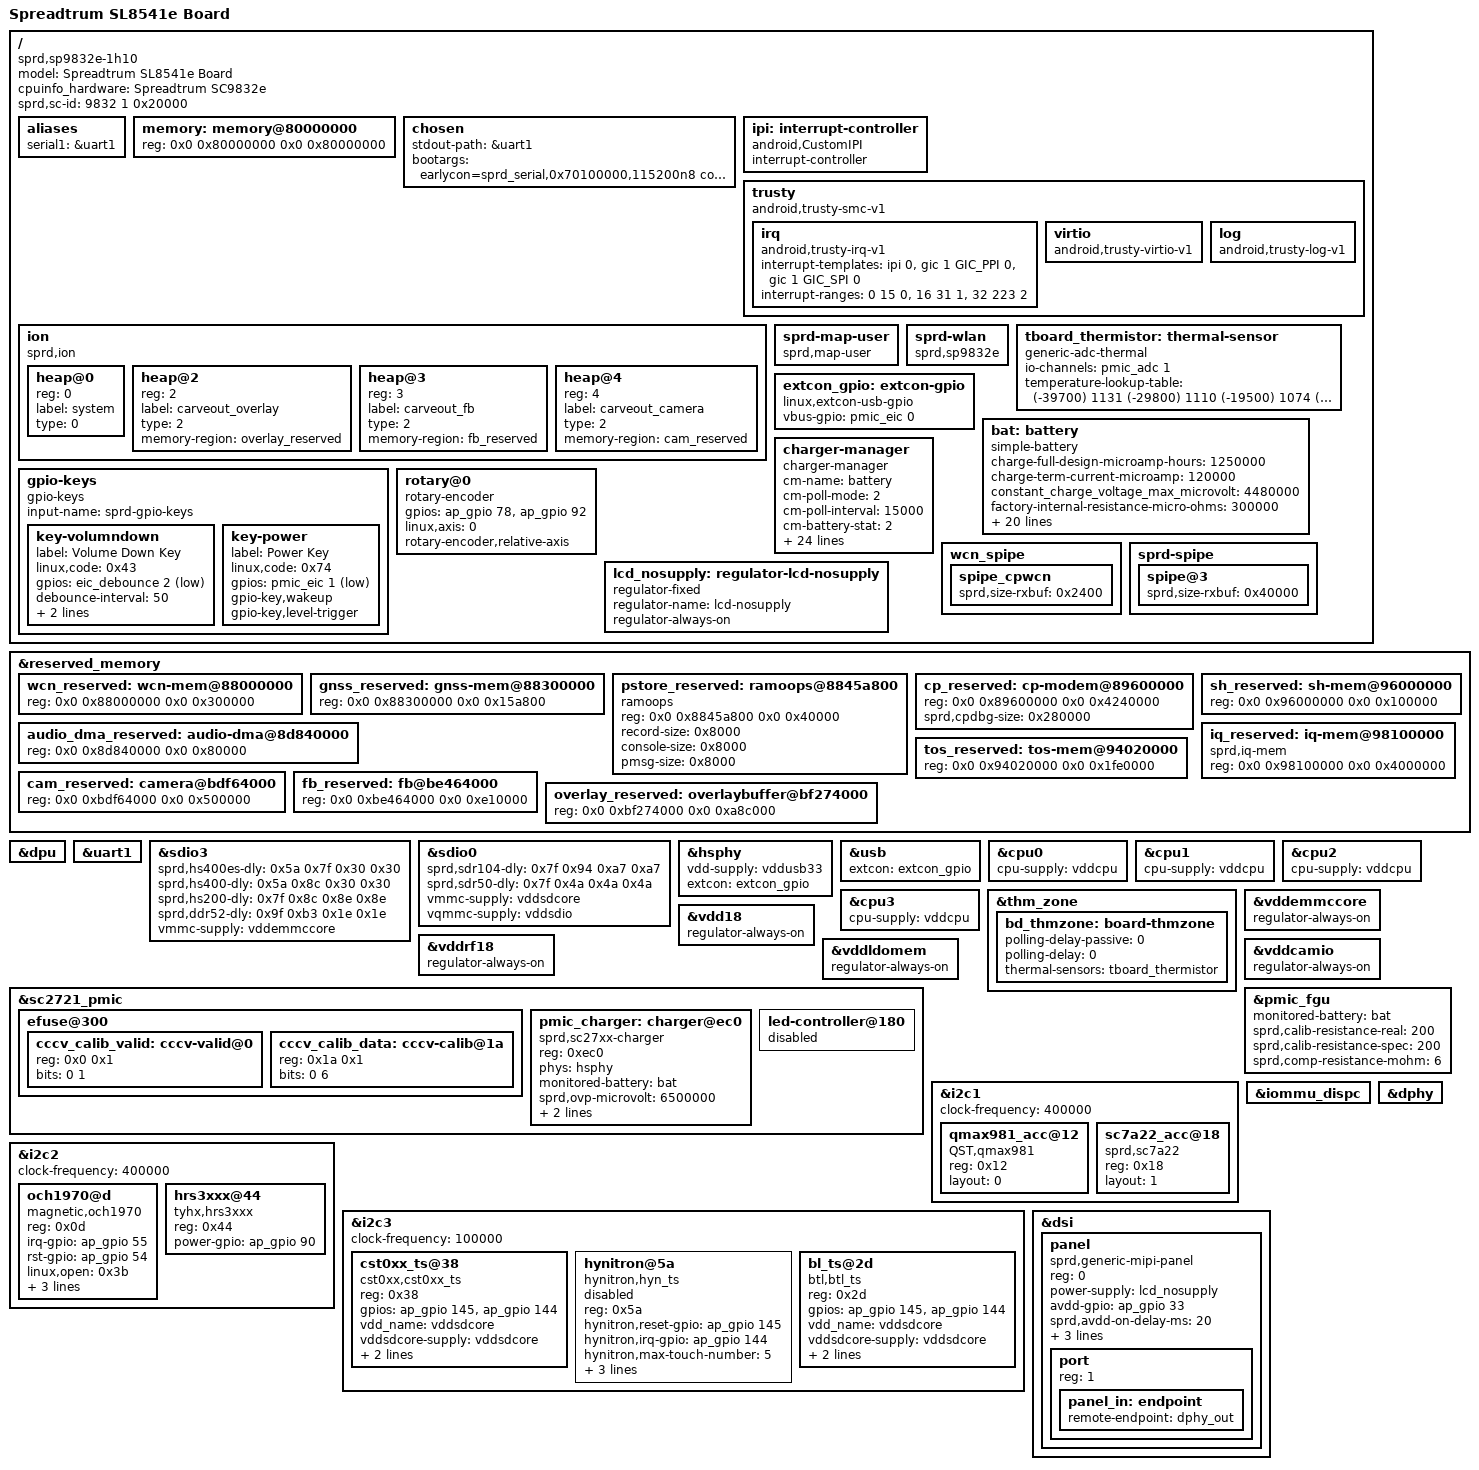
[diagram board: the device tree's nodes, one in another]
/*
 * DM82 watch (SC9832E / SC2721) board DTS for the 4.14 tree
 *
 * Hardware values come from the decompiled stock DT of the watch
 * (devices/dm82/stock.dts and SPEC.md of the 4.4 tree). The binding names are
 * the ones the 4.14 drivers read. devices/dm82/DTS_414.md has the node by node
 * table and the open points; the method is the one of the DM63 and MT108 files
 * (devices/dm63/DTS_414.md, devices/mt108/DTS_414.md).
 *
 * Compile only, nothing here has run on a watch.
 *
 * This file is licensed under a dual GPLv2 or X11 license.
 */
/dts-v1/;

#include <dt-bindings/gpio/gpio.h>
#include "sc9832e.dtsi"
#include "sp9832e-mach.dtsi"
#include "sc9832e-wcn.dtsi"
#include "sc2721.dtsi"
#include "lcd/lcd_co5300_oled175_mipi.dtsi"

/ {
	model = "Spreadtrum SL8541e Board";
	compatible = "sprd,sp9832e-1h10", "sprd,sc9832e";
	cpuinfo_hardware = "Spreadtrum SC9832e";
	sprd,sc-id = <9832 1 0x20000>;

	aliases {
		serial1 = &uart1;
	};

	/* stock: memory@80000000, 2 GiB window (MemTotal is lower, see reserved-memory) */
	memory: memory@80000000 {
		device_type = "memory";
		reg = <0x0 0x80000000 0x0 0x80000000>;
	};

	/* bootargs exactly as stock */
	chosen {
		stdout-path = &uart1;
		bootargs = "earlycon=sprd_serial,0x70100000,115200n8 console=ttyS1,115200n8 loglevel=1 init=/init root=/dev/ram0 rw androidboot.hardware=sl8541e_1h10";
	};

	ipi: interrupt-controller {
		compatible = "android,CustomIPI";
		#interrupt-cells = <1>;
		interrupt-controller;
	};

	trusty {
		compatible = "android,trusty-smc-v1";

		irq {
			compatible = "android,trusty-irq-v1";
			interrupt-templates = <&ipi 0>,
						<&gic 1 GIC_PPI 0>,
						<&gic 1 GIC_SPI 0>;
			interrupt-ranges = < 0  15 0>,
						<16  31 1>,
						<32 223 2>;
		};

		virtio {
			compatible = "android,trusty-virtio-v1";
		};

		log {
			compatible = "android,trusty-log-v1";
		};
	};

	/*
	 * stock ion heaps. The 4.14 sprd_ion driver reads reg, label, type and
	 * memory-region of each child. The stock "phys-offset" property is not
	 * read by 4.14 and is dropped.
	 */
	ion {
		compatible = "sprd,ion";
		#address-cells = <1>;
		#size-cells = <0>;

		heap@0 {
			reg = <0>;
			label = "system";
			type = <0>;
		};

		heap@2 {
			reg = <2>;
			label = "carveout_overlay";
			type = <2>;
			memory-region = <&overlay_reserved>;
		};

		heap@3 {
			reg = <3>;
			label = "carveout_fb";
			type = <2>;
			memory-region = <&fb_reserved>;
		};

		heap@4 {
			reg = <4>;
			label = "carveout_camera";
			type = <2>;
			memory-region = <&cam_reserved>;
		};
	};

	/* 4.14 compatible is "sprd,map-user" (stock: "sprd,sprd_map_user") */
	sprd-map-user {
		compatible = "sprd,map-user";
	};

	sprd-wlan {
		compatible = "sprd,sp9832e";
	};

	/*
	 * Board NTC (stock bd-tsensor@10, io-channel 3). The stock channel
	 * numbers are 4.4 logical channels (even = big scale, odd = small
	 * scale, two per hardware channel): 3 -> ADCI1 = hardware channel 1,
	 * which is the 4.14 channel number. Table: stock temp-tab-val (mV) and
	 * temp-tab-temp ((value - 1000) / 10 degC) converted to the
	 * generic-adc-thermal format (mV, milli degC).
	 */
	tboard_thermistor: thermal-sensor {
		compatible = "generic-adc-thermal";
		#thermal-sensor-cells = <0>;
		io-channels = <&pmic_adc 1>;
		io-channel-names = "sensor-channel";
		temperature-lookup-table = <	(-39700) 1131
						(-29800) 1110
						(-19500) 1074
						(-4800) 983
						10100 838
						24800 654
						44900 413
						54900 316
						64900 238
						74900 178
						84900 133
						94900 100
						104900 75
						114900 57
						124900 43 >;
	};

	/*
	 * USB cable detection. Stock: musb "sprd,cable-detection-method" =
	 * "gpios", "sprd,vbus-gpios" = PMIC EIC 0 (active high), no ID gpio.
	 * 4.14 takes the cable as an extcon device: VBUS from the gpio extcon.
	 */
	extcon_gpio: extcon-gpio {
		compatible = "linux,extcon-usb-gpio";
		vbus-gpio = <&pmic_eic 0 GPIO_ACTIVE_HIGH>;
	};

	/*
	 * Battery (stock "battery" node, sprd,sprd-battery) as a simple-battery
	 * with the property names this tree's power_supply_get_battery_info()
	 * reads (note the underscore name of the two constant_charge_* ones).
	 *
	 *   cnom 0x4e2 = 1250 mAh             charge-full-design-microamp-hours
	 *   rint 0x12c = 300 mOhm             factory-internal-resistance-micro-ohms
	 *   chg-end-cur 0x78 = 120 mA         charge-term-current-microamp
	 *   chg-end-vol 0x1180 = 4480 mV      constant_charge_voltage_max_microvolt
	 *   alm-vol 0xd7a = 3450 mV           voltage-min-design-microvolt
	 *                                     (low voltage alarm, same role, see SC2721_FGU_MAP.md)
	 *   ocv-tab-vol (mV) / ocv-tab-cap    ocv-capacity-table-0 (uV, percent), 20 degC
	 *   temp-tab-val (mV) / temp-tab-temp voltage-temp-table (uV, deci degC + 1000)
	 *                                     (temp-support 1, the table is the DM63 one)
	 *   adp-*-cur / adp-*-cur-limit       charge-*-current-microamp <current limit>
	 *                                     sdp/cdp/dcp 0x28a = 650 mA, unknown 0x276 = 630 mA;
	 *                                     limits 500 / 1500 / 3000 / 500 mA
	 *
	 * 4480 mV is representable by the SC2721 charger model
	 * (sc2721_cv_model()): END_V 1 (4300 mV) plus round(180 / 7.5) = 24 code
	 * steps over the efuse calibration, bit 0 of the code cleared. That holds
	 * for the calibrations 0..39 (code <= 0x3f), the default 0x20 gives code
	 * 56, exactly 4480 mV for even calibrations and 4472.5 mV for odd ones.
	 * For calibrations 40..63 the model cannot represent 4480 mV and
	 * sc2721_set_termination_voltage() returns -EINVAL (nothing written).
	 * The efuse calibration of the unit was not read. The jeita zone CV
	 * below is the stock 4450 mV (representable up to calibration 43).
	 * The stock chg-bat-safety-vol 4500 mV and rechg-vol 4320 mV have no
	 * 4.14 counterpart.
	 *
	 * TODO: stock cnom-temp-tab and rint-temp-tab (capacity and resistance
	 * against temperature) are not mapped: the 4.4 tables are scaled
	 * (cnom 1800/1300/1070/1000 permille, rint 200/450/650/1100 at
	 * 1020/1010/1000/990, same tables as the DM63) and the 4.14
	 * capacity-temp-table and resistance-temp-table use value / 10 degC,
	 * units not proven equal.
	 */
	bat: battery {
		compatible = "simple-battery";
		charge-full-design-microamp-hours = <1250000>;
		charge-term-current-microamp = <120000>;
		constant_charge_voltage_max_microvolt = <4480000>;
		factory-internal-resistance-micro-ohms = <300000>;
		voltage-min-design-microvolt = <3450000>;
		ocv-capacity-celsius = <20>;
		ocv-capacity-table-0 = <4418000 100>, <4350000 95>, <4294000 90>,
				       <4235000 85>, <4175000 80>, <4118000 75>,
				       <4065000 70>, <4016000 65>, <3970000 60>,
				       <3909000 55>, <3873000 50>, <3846000 45>,
				       <3823000 40>, <3805000 35>, <3789000 30>,
				       <3768000 25>, <3749000 20>, <3723000 15>,
				       <3696000 10>, <3681000 5>, <3400000 0>;
		voltage-temp-table = <1052000 750>, <953000 800>, <858000 850>,
				     <762000 900>, <671000 950>, <584000 1000>,
				     <504000 1050>, <434000 1100>, <372000 1150>,
				     <318000 1200>, <271000 1250>, <234000 1300>,
				     <198000 1350>, <165000 1400>, <140000 1450>,
				     <119000 1500>, <104000 1550>, <88000 1600>;
		charge-sdp-current-microamp = <650000 500000>;
		charge-dcp-current-microamp = <650000 3000000>;
		charge-cdp-current-microamp = <650000 1500000>;
		charge-unknown-current-microamp = <630000 500000>;
	};

	/*
	 * charger-manager (psy based in this tree, no regulator child: the
	 * charger is the internal SC2721 one and is started by the charger
	 * driver and by STATUS writes from charger-manager).
	 * [stock] = value derived from the stock battery node, [base] = value
	 * of the 4.14 sl8541e-1h10 reference board, no stock equivalent.
	 *
	 * cm-jeita-temp-table: the five entry stock table (conversion as in
	 * devices/dm63/DTS_414.md): jeita-temp-tab 900 1000 1100 1450 1500,
	 * recovery 930 1030 1130 1420 1470, jeita-cur-tab (mA) 0 100 500 0x7fff
	 * 700 0, jeita-cccv-tab 0x1162 = 4450 mV in every zone. Zone 0 and zone 5
	 * stop charging. As in the stock 4.4 sprd_battery.c, every zone current
	 * is capped to the adapter current (650 mA, unknown adapter 630 mA,
	 * rounded down to the 50 mA step) by the charger
	 * (sc2720_charger_set_current()) and every zone CV to the battery
	 * maximum (4480 mV, above the zone CV, so no cap acts); the
	 * stock 0x7fff (no limit) zone is written as 32767 mA so the adapter
	 * current applies.
	 * cm-wdt-interval is left out: stock chg-wdt is disabled and the
	 * charger driver has no watchdog property.
	 */
	charger-manager {
		compatible = "charger-manager";
		cm-name = "battery";
		cm-poll-mode = <2>;			/* [base] */
		cm-poll-interval = <15000>;		/* [base] */
		cm-battery-stat = <2>;			/* [base] fuel gauge PRESENT (always 1 here) */

		cm-fullbatt-vchkdrop-ms = <30000>;	/* [base] */
		cm-fullbatt-vchkdrop-volt = <60000>;	/* [base] */
		cm-fullbatt-voltage = <4450000>;	/* [stock] chg-end-vol-check 0x1162 = 4450 mV */
		cm-fullbatt-current = <120000>;		/* [stock] chg-end-cur 0x78 = 120 mA */
		cm-fullbatt-capacity = <100>;		/* [base] */

		cm-num-chargers = <1>;
		cm-chargers = "sc2721_charger";
		cm-fuel-gauge = "sc27xx-fgu";

		/* [stock] outer limits of jeita-temp-tab: -10 and 50 degC, 3 degC hysteresis */
		cm-jeita-temp-table = <900 930 0 4450000>,
				      <1000 1030 100000 4450000>,
				      <1100 1130 500000 4450000>,
				      <1450 1420 32767000 4450000>,
				      <1500 1470 700000 4450000>;

		cm-battery-cold = <100>;
		cm-battery-cold-in-minus;
		cm-battery-hot = <500>;
		cm-battery-temp-diff = <30>;

		cm-charging-max = <21600000>;		/* [stock] chg-timeout 21600 s */
		cm-discharging-max = <2700000>;		/* [base] */

		cm-shutdown-voltage = <3050000>;	/* [stock] soft-vbat-uvlo */
		cm-tickle-time-out = <1500>;		/* [base] */
		cm-one-cap-time = <30>;			/* [stock] cap-one-per-time */

		cm-charge-voltage-max = <6500000>;	/* [stock] ovp-stop */
		cm-charge-voltage-drop = <700000>;	/* [stock] ovp-stop - ovp-restart (6500 - 5800) */
	};

	/*
	 * stock gpio-keys. The 4.14 gpio_keys reads gpio-key,wakeup and
	 * debounce-interval; gpio-key,level-trigger is not read (4.14 takes the
	 * trigger from the gpio, both edges) and is kept for reference only.
	 * linux,code values are the stock ones (0x43 = 67, 0x74 = 116).
	 */
	gpio-keys {
		compatible = "gpio-keys";
		input-name = "sprd-gpio-keys";

		key-volumndown {
			label = "Volume Down Key";
			linux,code = <0x43>;
			/* stock: ap-eic (40210000) pin 2 = debounce EIC channel 2 */
			gpios = <&eic_debounce 2 GPIO_ACTIVE_LOW>;
			debounce-interval = <50>;
			gpio-key,wakeup;
			gpio-key,level-trigger;
		};

		key-power {
			label = "Power Key";
			linux,code = <0x74>;
			gpios = <&pmic_eic 1 GPIO_ACTIVE_LOW>;
			gpio-key,wakeup;
			gpio-key,level-trigger;
		};
	};

	/* stock rotary crown, mainline rotary-encoder binding */
	rotary@0 {
		compatible = "rotary-encoder";
		gpios = <&ap_gpio 78 GPIO_ACTIVE_HIGH>,
			<&ap_gpio 92 GPIO_ACTIVE_HIGH>;
		linux,axis = <0>;
		rotary-encoder,relative-axis;
	};
};

/*
 * SIPC pipes. sc9832e-wcn.dtsi / sc9832e-modem.dtsi carry the same layout as
 * stock except two ring buffer sizes (base values 0x1000 and 0x20000, the
 * latter with a comment that says 256 KiB); stock values used.
 */
/ {
	wcn_spipe {
		spipe_cpwcn {
			sprd,size-rxbuf = <0x2400>;
		};
	};

	sprd-spipe {
		spipe@3 {
			sprd,size-rxbuf = <0x40000>;	/* sdiag_lte */
		};
	};
};

/*
 * reserved-memory: addresses and sizes copied from the stock DT. The
 * sl8541e/mach.dtsi layout (1 GiB board) differs, so the nodes that differ are
 * deleted and declared again with the same labels.
 *
 * Stock has no logo buffer: logo_reserved (0x9e000000, mach.dtsi) and the
 * dpu "sprd,logo-memory" property that points at it are removed (the driver
 * only prints "no sprd,logo-memory specified"). TODO with the display step.
 */
/delete-node/ &logo_reserved;
/delete-node/ &wcn_reserved;
/delete-node/ &gnss_reserved;
/delete-node/ &cp_reserved;
/delete-node/ &iq_reserved;
/delete-node/ &tos_reserved;
/delete-node/ &pstore_reserved;

&reserved_memory {
	wcn_reserved: wcn-mem@88000000 {
		reg = <0x0 0x88000000 0x0 0x300000>;
	};

	gnss_reserved: gnss-mem@88300000 {
		reg = <0x0 0x88300000 0x0 0x15a800>;
	};

	/* ramoops lives here in stock (ramoops node memory-region = pstore) */
	pstore_reserved: ramoops@8845a800 {
		compatible = "ramoops";
		reg = <0x0 0x8845a800 0x0 0x40000>;
		record-size = <0x8000>;
		console-size = <0x8000>;
		pmsg-size = <0x8000>;
	};

	/* stock size includes the 0x280000 debug region (sprd,cpdbg-size) */
	cp_reserved: cp-modem@89600000 {
		reg = <0x0 0x89600000 0x0 0x4240000>;
		sprd,cpdbg-size = <0x280000>;
	};

	audio_dma_reserved: audio-dma@8d840000 {
		reg = <0x0 0x8d840000 0x0 0x80000>;
	};

	tos_reserved: tos-mem@94020000 {
		reg = <0x0 0x94020000 0x0 0x1fe0000>;
	};

	sh_reserved: sh-mem@96000000 {
		reg = <0x0 0x96000000 0x0 0x100000>;
	};

	iq_reserved: iq-mem@98100000 {
		compatible = "sprd,iq-mem";
		reg = <0x0 0x98100000 0x0 0x4000000>;
	};

	cam_reserved: camera@bdf64000 {
		reg = <0x0 0xbdf64000 0x0 0x500000>;
	};

	fb_reserved: fb@be464000 {
		reg = <0x0 0xbe464000 0x0 0xe10000>;
	};

	overlay_reserved: overlaybuffer@bf274000 {
		reg = <0x0 0xbf274000 0x0 0xa8c000>;
	};
};

&dpu {
	/delete-property/ sprd,logo-memory;
	status = "okay";
};

&uart1 {
	status = "okay";
};

/*
 * eMMC (stock sdio@20600000) and SD (sdio@20300000). The 4.14 driver names
 * (sprd,sdhc-r10, sprd,*-dly, sprd,sdio-adma) are the same as stock. Delays,
 * bus width, caps and supplies are the stock ones (mach.dtsi carries the
 * reference board delays for the eMMC, overridden here).
 */
&sdio3 {
	sprd,hs400es-dly = <0x5a 0x7f 0x30 0x30>;
	sprd,hs400-dly = <0x5a 0x8c 0x30 0x30>;
	sprd,hs200-dly = <0x7f 0x8c 0x8e 0x8e>;
	sprd,ddr52-dly = <0x9f 0xb3 0x1e 0x1e>;
	vmmc-supply = <&vddemmccore>;
};

&sdio0 {
	sprd,sdr104-dly = <0x7f 0x94 0xa7 0xa7>;
	sprd,sdr50-dly = <0x7f 0x4a 0x4a 0x4a>;
	vmmc-supply = <&vddsdcore>;
	vqmmc-supply = <&vddsdio>;
};

/*
 * USB. Stock: sprd,usb (musb), dr-mode "peripheral",
 * sprd,cable-detection-method "gpios" (the DM63 has "typec"), vbus-gpios =
 * PMIC EIC 0, no usb-id gpio; phy sprd,usb-phy with tune-value 0x5af33,
 * vdd-voltage 3300000 and vdd-supply = vddusb33. 4.14: sprd,sharkle-musb /
 * sprd,sharkle-phy (already in sharkle.dtsi, same tune-value and
 * vdd-voltage). The 4.14 musb takes its mode from Kconfig (dr-mode is not
 * read) and the cable from extcon: the gpio extcon only, the stock method
 * is "gpios", so the typec extcon of the DM63 file is not listed.
 *
 * TODO: no OTG VBUS regulator is mapped (stock has none in the DT), so
 * host mode has no vbus-supply.
 */
&hsphy {
	vdd-supply = <&vddusb33>;
	extcon = <&extcon_gpio>;
};

&usb {
	extcon = <&extcon_gpio>;
};

&cpu0 {
	cpu-supply = <&vddcpu>;
};

&cpu1 {
	cpu-supply = <&vddcpu>;
};

&cpu2 {
	cpu-supply = <&vddcpu>;
};

&cpu3 {
	cpu-supply = <&vddcpu>;
};

&thm_zone {
	bd_thmzone: board-thmzone {
		polling-delay-passive = <0>;
		polling-delay = <0>;
		thermal-sensors = <&tboard_thermistor>;
	};
};

/*
 * Regulators. Stock marks these "sprd,default-on" (the 4.4 driver switches
 * them on at probe and never again). In 4.14 a regulator that nothing in the
 * DT consumes is switched off in regulator_late_cleanup(), so the ones that
 * stock keeps on and that have no DT consumer here are regulator-always-on.
 * vddemmccore is the boot storage supply and is kept on as well.
 * (vddcpu/vddcore/vddmem/vddgen/vdd28/vdddcxo are always-on in sc2721.dtsi.)
 * vddsdcore, vddsdio and vddusb33 have consumers (sdio0, touch, hsphy).
 *
 * The sl8541e reference board disables vddrf18 and vddldomem; stock DM63
 * keeps both on.
 */
&vddemmccore {
	regulator-always-on;
};

&vdd18 {
	regulator-always-on;
};

&vddrf18 {
	regulator-always-on;
};

&vddldomem {
	regulator-always-on;
};

&vddcamio {
	regulator-always-on;
};

/*
 * PMIC.
 *
 * efuse nvmem cells for the charger. The 4.14 sc27xx efuse driver exposes
 * 32 blocks of 16 bits as a byte addressed nvmem (stride 1, word size 1):
 * a cell "reg = <offset size>" is a byte offset, block N starts at byte
 * 2 * N, and the read returns the block shifted right by 8 * (offset % 2).
 * The core "bits = <bit_offset nbits>" property selects bits inside the cell,
 * and with it set the cell size is rounded up to whole bytes of
 * (bit_offset + nbits).
 *
 *   4.4 stock: valid flag = block 0 bit 0           -> byte offset 0 * 2 = 0x00, bits <0 1>
 *   4.4 stock: BITSINDEX(13, 0), 6 bits (16 bit block, sprd,block-width = 16)
 *                                                   -> byte offset 13 * 2 = 0x1a, bits <0 6>
 *
 * The same byte offsets are used by the existing cells efuse_blk0 (0x0) and
 * cc_cal (0x1a, whole block 13, used by the typec node); the new cells only
 * select the bits the charger needs. sc2720_charger.c reads
 * "cccv_calib_valid" first (BIT(0) must be set, else the 4.4 default 0x20
 * is used) and then "cccv_calib" (6 bits, masked with 0x3f).
 */
&sc2721_pmic {
	efuse@300 {
		cccv_calib_valid: cccv-valid@0 {
			reg = <0x0 0x1>;
			bits = <0 1>;
		};

		cccv_calib_data: cccv-calib@1a {
			reg = <0x1a 0x1>;
			bits = <0 6>;
		};
	};

	/*
	 * Stock charger@ec0 "sprd,sc2721-charger", reg 0xec0. The mfd cell
	 * matches "sprd,sc27xx-charger", the driver "sprd,sc2721-charger".
	 * "phys" is the USB phy the charger driver registers a notifier on.
	 *
	 * sprd,ovp-microvolt: stock battery ovp-stop 0x1964 = 6500 mV, written
	 * to the input OVP field (code 9).
	 *
	 * TODO (not implemented in the 4.14 driver, stock values): chg-cv-gpios
	 * = PMIC EIC 4, chg-ovi-gpios = PMIC EIC 6, ovp-restart 5800 mV,
	 * chg-timer@0 (irq 7), fast-charger@900 (disabled in stock), chg-wdt@80
	 * (disabled in stock), ITERM and recharge bits.
	 */
	pmic_charger: charger@ec0 {
		compatible = "sprd,sc27xx-charger", "sprd,sc2721-charger";
		reg = <0xec0>;
		phys = <&hsphy>;
		monitored-battery = <&bat>;
		sprd,ovp-microvolt = <6500000>;
		nvmem-cells = <&cccv_calib_data>, <&cccv_calib_valid>;
		nvmem-cell-names = "cccv_calib", "cccv_calib_valid";
	};
};

/*
 * Fuel gauge. Stock fgu@a00 (reg 0xa00, irq 3, ocv-type 1) is the base
 * node; compatible order in sc2721.dtsi lists sprd,sc2721-fgu before
 * sprd,sc2720-fgu so the SC2721 match data is used. io-channels of the base
 * node: bat-temp = 0 (stock adc_temp, logical channel 1 = hardware 0) and
 * charge-vol = 14 (stock adc_vchg, logical 36 = hardware 14).
 *
 * rsense-real/spec: stock 200/200, only the ratio is used (1).
 * comp-resistance: stock temp-comp-res 0x06 = 6 mOhm.
 *
 * Stock has no battery detect gpio and treats the battery as present: the
 * inherited bat-detect-gpio (PMIC EIC 9) is deleted, the gauge then reports
 * the battery as always present and requests no detection interrupt.
 */
&pmic_fgu {
	/delete-property/ bat-detect-gpio;
	monitored-battery = <&bat>;
	sprd,calib-resistance-real = <200>;
	sprd,calib-resistance-spec = <200>;
	sprd,comp-resistance-mohm = <6>;
};

/*
 * I2C. Frequencies are the stock ones (i2c0 400k = 0x61a80, i2c1 400k, i2c2
 * 400k, i2c3 100k = 0x186a0).
 *
 * i2c0 (stock: camera sensors 0x20/0x21) and i2c4 (stock: disabled, flash
 * ocp8137 0x63, fan54015 0x6a) stay disabled. TODO camera: no 4.14 camera
 * driver, stock sensor-main@20 / sensor-sub@21 with reset gpios 45/44 and
 * power-down gpios 47/46 on ap_gpio.
 *
 * The stock DT enables every candidate part of a family (it is one image
 * for several builds), SPEC.md does not say which are fitted. A node whose
 * chip is absent fails its probe on the missing ACK, as in stock.
 */
&i2c1 {
	status = "okay";
	clock-frequency = <400000>;

	/*
	 * stock qmax981_acc@12: layout 0 (layout-qma6100p 5 is not read by the
	 * 4.14 qma6981 port).
	 */
	qmax981_acc@12 {
		compatible = "QST,qmax981";
		reg = <0x12>;
		layout = <0>;
	};

	/*
	 * stock sc7a22_acc@18: layout 1 (the 4.14 port reads it as an index
	 * into its axis maps). The stock angle 0x75 is not read and the stock
	 * irq-gpio (ap_gpio 93) is not read either (polled).
	 */
	sc7a22_acc@18 {
		compatible = "sprd,sc7a22";
		reg = <0x18>;
		layout = <1>;
	};
};

&i2c2 {
	status = "okay";
	clock-frequency = <400000>;

	/*
	 * stock och1970@0d (hall sensor), interrupt driven in the 4.14 port:
	 * irq-gpio stock ap_gpio 55, rst-gpio ap_gpio 54, key codes
	 * linux,open 0x3b / linux,close 0x42 / linux,back 0x3c / linux,front
	 * 0x3d. No threshold properties: gen1 (DM82) fixed axis and thresholds.
	 */
	och1970@d {
		compatible = "magnetic,och1970";
		reg = <0x0d>;
		irq-gpio = <&ap_gpio 55 GPIO_ACTIVE_HIGH>;
		rst-gpio = <&ap_gpio 54 GPIO_ACTIVE_HIGH>;
		linux,open = <0x3b>;
		linux,close = <0x42>;
		linux,back = <0x3c>;
		linux,front = <0x3d>;
	};

	/* heart rate, stock hrs3xxx@0x44, power-gpio ap_gpio 90 */
	hrs3xxx@44 {
		compatible = "tyhx,hrs3xxx";
		reg = <0x44>;
		power-gpio = <&ap_gpio 90 GPIO_ACTIVE_HIGH>;
	};

	/*
	 * TODO not mapped: stock bd1xxx_hr@38 (heartrate,bd1xxx, power-gpio
	 * ap_gpio 130, stock config HEARTRATE_BD1820) has no 4.14 driver.
	 */
};

&i2c3 {
	status = "okay";
	clock-frequency = <100000>;

	/*
	 * Touch. The stock DT lists three candidates on this bus, all sharing
	 * reset ap_gpio 145 and irq ap_gpio 144 and all enabled; SPEC.md does
	 * not say which is fitted. The CST0xx (0x38) is enabled, as on the DM63
	 * and MT108. Stock cst0xx_ts@38: gpios = <ap_gpio 145 (reset)>,
	 * <ap_gpio 144 (irq)> in this order, vdd_name "vddsdcore", TP_MAX_X
	 * 0x1d4 = 468, TP_MAX_Y 0x1d2 = 466. The driver gets the supply with
	 * devm_regulator_get(dev, vdd_name), i.e. the DT property
	 * "<vdd_name>-supply", which stock did not need. The stock
	 * "virtualkeys" property is not read by the 4.14 port.
	 */
	cst0xx_ts@38 {
		compatible = "cst0xx,cst0xx_ts";
		reg = <0x38>;
		gpios = <&ap_gpio 145 GPIO_ACTIVE_HIGH>,
			<&ap_gpio 144 GPIO_ACTIVE_HIGH>;
		vdd_name = "vddsdcore";
		vddsdcore-supply = <&vddsdcore>;
		TP_MAX_X = <468>;
		TP_MAX_Y = <466>;
	};

	/*
	 * Stock hynitron@5a (hynitron,hyn_ts, SPEC.md: 5 touches, display
	 * coords 0x1d4 x 0x1d2 = 468 x 466) has a 4.14 driver but shares reset
	 * and irq with the CST0xx node; both enabled would have the second
	 * probe pull the shared reset line after the first chip is set up.
	 * Disabled until the fitted chip is known (i2cdetect on the unit);
	 * for a unit with this chip enable it and disable cst0xx_ts@38.
	 * TODO.
	 */
	hynitron@5a {
		compatible = "hynitron,hyn_ts";
		reg = <0x5a>;
		hynitron,reset-gpio = <&ap_gpio 145 GPIO_ACTIVE_HIGH>;
		hynitron,irq-gpio = <&ap_gpio 144 GPIO_ACTIVE_HIGH>;
		hynitron,max-touch-number = <5>;
		hynitron,display-coords = <468 466>;
		vdd_name = "vddsdcore";
		vddsdcore-supply = <&vddsdcore>;
		status = "disabled";
	};

	/*
	 * stock bl_ts@2d (btl,btl_ts, Betterlife BL6133/BL6138): gpios =
	 * <ap_gpio 145 (reset)>, <ap_gpio 144 (irq)> in this order, vdd_name
	 * "vddsdcore", TP_MAX_X 0x1d4 (468), TP_MAX_Y 0x1d2 (466). "virtualkeys" is
	 * not read by the 4.14 btl_ts port. It shares reset and irq with the
	 * other touch nodes and is placed after them; it identifies the chip in
	 * probe and fails with -ENODEV (or -EBUSY while another touch driver
	 * holds the gpios) on a unit with another controller.
	 */
	bl_ts@2d {
		compatible = "btl,btl_ts";
		reg = <0x2d>;
		gpios = <&ap_gpio 145 GPIO_ACTIVE_HIGH>,
			<&ap_gpio 144 GPIO_ACTIVE_HIGH>;
		vdd_name = "vddsdcore";
		vddsdcore-supply = <&vddsdcore>;
		TP_MAX_X = <468>;
		TP_MAX_Y = <466>;
	};
};

/*
 * TODO not mapped: stock keypad@40250000 (sprd,v1-keypad, 3 x 3 matrix,
 * status okay, no key map in the DT) has no driver in the 4.14 list of this
 * work; the keys of the unit are the gpio-keys and the rotary encoder above.
 *
 * Stock bltc-rgb@180 (sprd,sc2721-bltc-rgb) is "disabled" on this watch, so
 * the led-controller of sc2721.dtsi is disabled here too (the MT108 enables it).
 */
&sc2721_pmic {
	led-controller@180 {
		status = "disabled";
	};
};

/*
 * Display. Stock panel (SPEC.md, U-Boot log): CO5300 AMOLED, 468 x 466, one
 * DSI lane, command mode, bpp 24 (U-Boot runs co5300_mipi_init and
 * co5300_readid reads 0x33 0x11). The stock DT has nine panel nodes and the
 * bootloader's lcd_id=ID<hex> picks one; only the CO5300 node
 * lcd5300175@5300175 (ID5300175, lcd_co5300_oled175_mipi) is converted
 * (lcd/lcd_co5300_oled175_mipi.dtsi, same conversion as the DM63 CO5300
 * panels, devices/dm63/PANEL_414.md). The other eight nodes (three 1.43 inch
 * OLEDs ICNA3310 / CH13613 / SH8601Z with the same 468 x 466 geometry,
 * ST7797, GC9B71, ST77916 CTO 1.50 (bpp 18), R63353, dummy) are not
 * converted; the controller read from U-Boot is the CO5300, but the lcd_id
 * the unit reports was never read (SPEC.md: "most likely" ID5300175,
 * unverified).
 *
 * dpu, iommu_dispc, dsi and dphy are enabled (the converted panel is bpp 24,
 * the 24 bit DPI width of the 4.14 dpu_lite_r1p0.c is correct for it).
 * Panel selection, as stock: lcd_id=ID<hex> must match sprd,lcd-id; lcd_name=
 * still wins. There is NO sprd,default-panel: SPEC.md does not state the
 * reported lcd_id, so without lcd_id= and lcd_name= the panel probe returns
 * -ENODEV (blank, no crash). Set it when the lcd_id is known.
 *
 * Stock power-on-sequence (gpio level delay-ms) 33 1 20, 50 1 20, 50 0 20,
 * 50 1 50: gpio 33 is avdd-gpio, gpio 50 is reset-gpio, the levels and
 * delays are in sprd,reset-on-sequence of the lcd dtsi; power-off 50 0 20,
 * 33 0 20 (reset low, then avdd low).
 *
 * Stock names no panel regulator, but the 4.14 panel driver needs a "power"
 * supply or its probe fails with -ENODEV (no full constraints on this
 * board), so the panel points at a fixed regulator without enable gpio.
 * Needs CONFIG_REGULATOR_FIXED_VOLTAGE (watch_414.fragment).
 *
 * TODO not mapped: stock sprd_backlight (pwm-backlight) is not used by the
 * OLED, the brightness is the oled-backlight of the lcd node. pwms stays
 * disabled. AOD (stock aod-in / aod-out, sprd_aod_idle) has no 4.14 port.
 */
/ {
	lcd_nosupply: regulator-lcd-nosupply {
		compatible = "regulator-fixed";
		regulator-name = "lcd-nosupply";
		regulator-always-on;
	};
};

&iommu_dispc {
	status = "okay";
};

&dsi {
	status = "okay";
	#address-cells = <1>;
	#size-cells = <0>;

	panel: panel {
		compatible = "sprd,generic-mipi-panel";
		#address-cells = <1>;
		#size-cells = <0>;
		reg = <0>;

		power-supply = <&lcd_nosupply>;
		avdd-gpio = <&ap_gpio 33 GPIO_ACTIVE_HIGH>;
		/*
		 * Stock power-on-sequence 33 1 20 (avdd, 20 ms) before the reset
		 * pulses; power-off-sequence 50 0 20, 33 0 20 (reset low, then
		 * avdd low).
		 */
		sprd,avdd-on-delay-ms = <20>;
		sprd,avdd-off-delay-ms = <20>;
		sprd,avdd-off-after-reset;
		reset-gpio = <&ap_gpio 50 GPIO_ACTIVE_HIGH>;

		port {
			reg = <1>;
			panel_in: endpoint {
				remote-endpoint = <&dphy_out>;
			};
		};
	};
};

&dphy {
	status = "okay";
};
